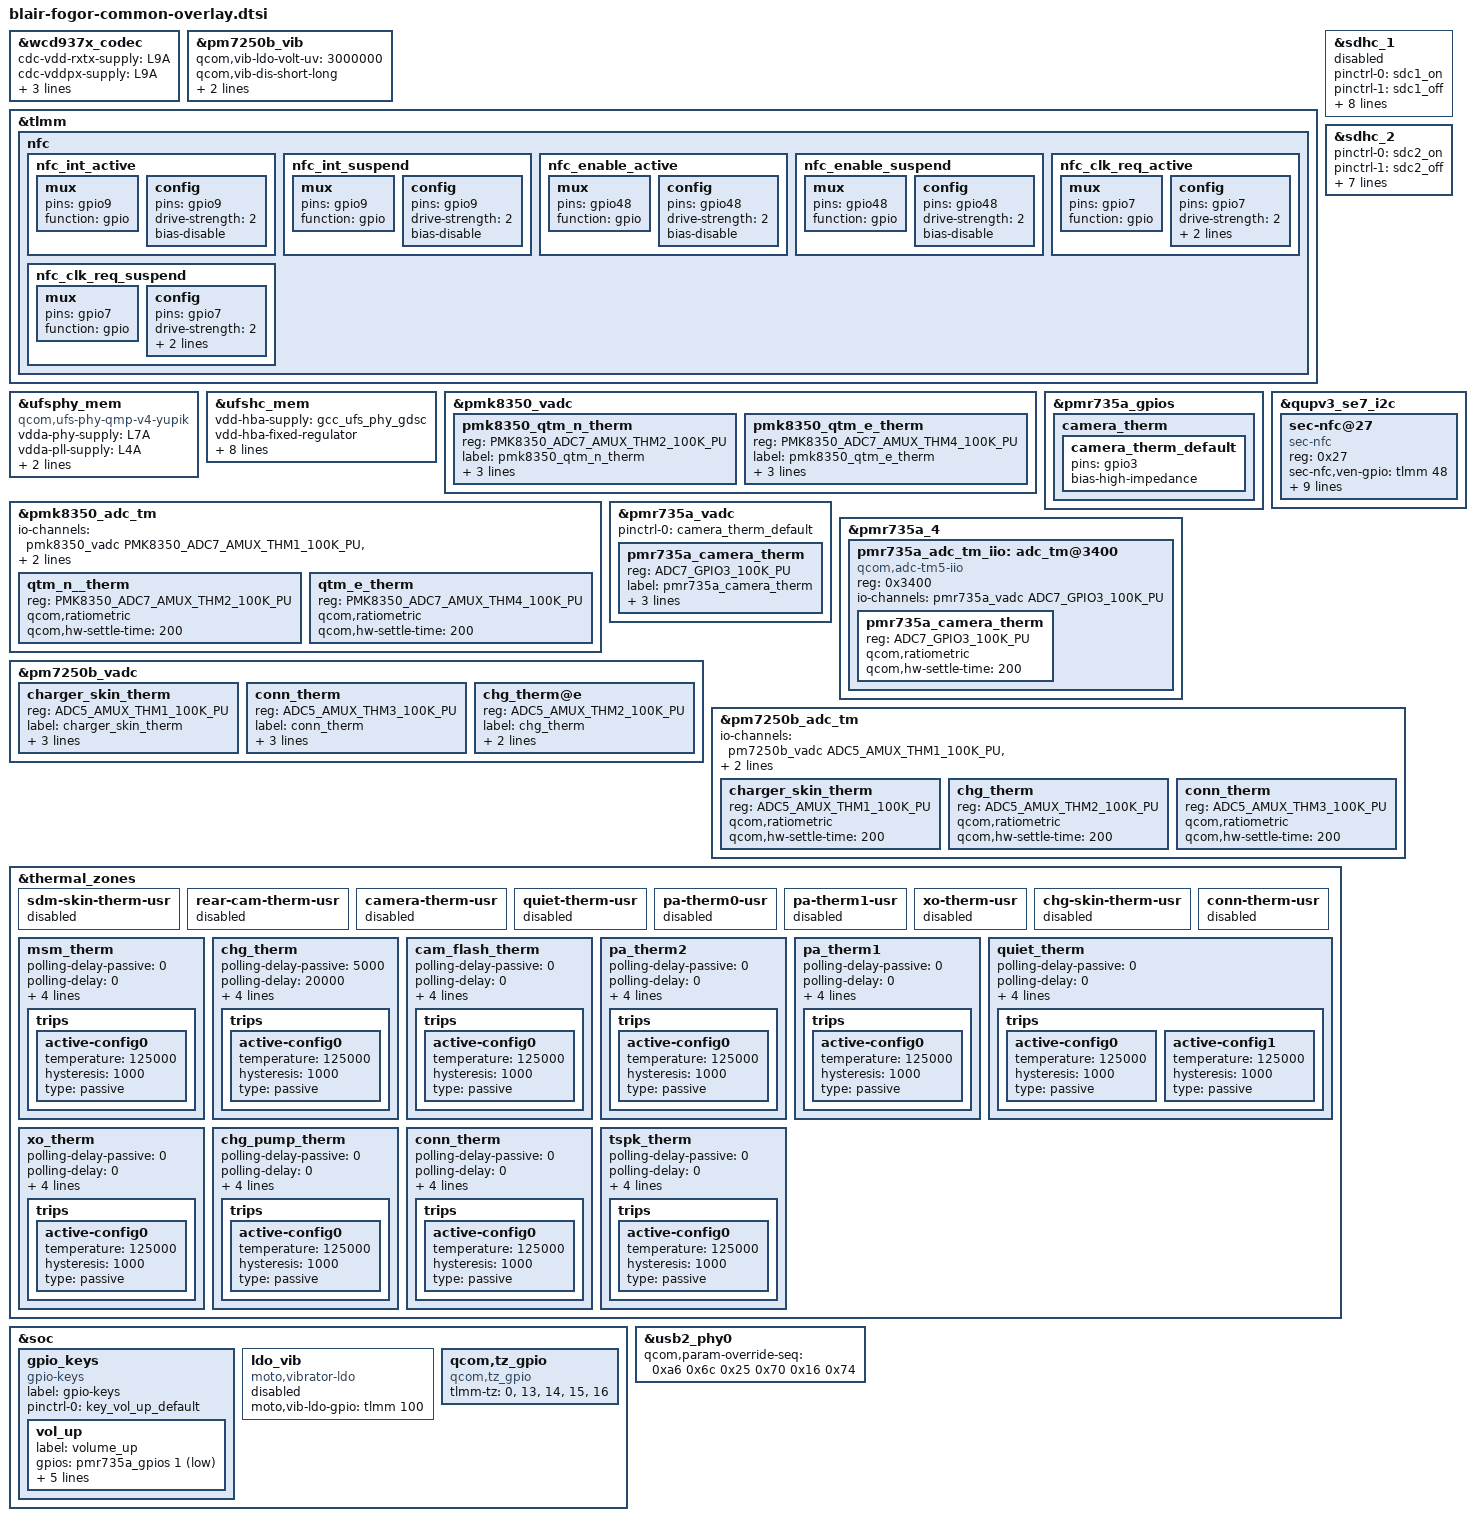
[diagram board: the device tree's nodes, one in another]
/* Copyright (c) 2023, The Linux Foundation. All rights reserved.
 *
 * This program is free software; you can redistribute it and/or modify
 * it under the terms of the GNU General Public License version 2 and
 * only version 2 as published by the Free Software Foundation.
 *
 * This program is distributed in the hope that it will be useful,
 * but WITHOUT ANY WARRANTY; without even the implied warranty of
 * MERCHANTABILITY or FITNESS FOR A PARTICULAR PURPOSE.  See the
 * GNU General Public License for more details.
 */
#include "holi-audio-fogor-overlay.dtsi"
#include <dt-bindings/gpio/gpio.h>
#include <dt-bindings/input/linux-event-codes.h>
#include "holi-pmic-overlay-pm6125.dtsi"
#include "holi-thermal-overlay-pm6125.dtsi"
#include "display/holi-sde-display-mtp-pm6125.dtsi"
#include "display/blair-sde-display-mtp.dtsi"
#include "fogor-fps-overlay.dtsi"
#include "fogor-display.dtsi"
#include "fogor-touchscreen.dtsi"
#include "fogor-sensors.dtsi"
#include "camera/blair-camera-sensor-mot-fogor-overlay.dtsi"
#include "fogor-wl286xx.dtsi"
#include "moto_therm_sys_temp.dtsi"
#include "blair-fogor-fmr-overlay.dtsi"

&wcd937x_codec {
	cdc-vdd-rxtx-supply = <&L9A>;
	cdc-vddpx-supply = <&L9A>;
	qcom,cdc-static-supplies = "cdc-vdd-rxtx",
				   "cdc-vddpx";
	/*
	 * Overriding cdc-vdd-mic-bias-supply to dummy value
	 * to avoid compilation errors as BOB is not definied
	 * for pm6125
	 */
	cdc-vdd-mic-bias-supply = <>;
};

&pm7250b_vib {
	qcom,vib-ldo-volt-uv = <3000000>;
	qcom,vib-dis-short-long;
	qcom,vib-dis-short-long-val = <70>;
	qcom,vib-ldo-volt-uv-long = <2600000>;
};

&tlmm {
	nfc {
		nfc_int_active: nfc_int_active {
			/* active state */
			mux {
				/* GPIO 9: NFC Read Interrupt */
				pins = "gpio9";
				function = "gpio";
			};

			config {
				pins = "gpio9";
				drive-strength = <2>; /* 2 MA */
				bias-disable;
			};
		};

		nfc_int_suspend: nfc_int_suspend {
			/* sleep state */
			mux {
				/* GPIO 9: NFC Read Interrupt */
				pins = "gpio9";
				function = "gpio";
			};

			config {
				pins = "gpio9";
				drive-strength = <2>; /* 2 MA */
				bias-disable;
			};
		};

		nfc_enable_active: nfc_enable_active {
			mux {
				pins = "gpio48";
				function = "gpio";
			};

			config {
				pins = "gpio48";
				drive-strength = <2>; /* 2 MA */
				bias-disable;
			};
		};

		nfc_enable_suspend: nfc_enable_suspend {
			mux {
				pins = "gpio48";
				function = "gpio";
			};

			config {
				pins = "gpio48";
				drive-strength = <2>; /* 2 MA */
				bias-disable;
			};
		};


		nfc_clk_req_active: nfc_clk_req_active {
			/* active state */
			mux {
				/* GPIO 7: NFC CLK Req*/
				pins = "gpio7";
				function = "gpio";
			};

			config {
				pins = "gpio7";
				drive-strength = <2>; /* 2 MA */
				bias-disable;
				input-enable;
			};
		};

		nfc_clk_req_suspend: nfc_clk_req_suspend {
			/* sleep state */
			mux {
				/* GPIO 7: NFC CLK Req */
				pins = "gpio7";
				function = "gpio";
			};

			config {
				pins = "gpio7";
				drive-strength = <2>; /* 2 MA */
				bias-disable;
				input-enable;
			};
		};
	};
};

/* Dummy LDO reference */
&sdhc_1 {
	status = "disabled";

	pinctrl-names = "default", "sleep";
	pinctrl-0 = <&sdc1_on>;
	pinctrl-1 = <&sdc1_off>;

	vdd-supply = <&L24A>;
	qcom,vdd-voltage-level = <2960000 2960000>;
	qcom,vdd-current-level = <0 570000>;

	vdd-io-supply = <&L11A>;
	qcom,vdd-io-always-on;
	qcom,vdd-io-lpm-sup;
	qcom,vdd-io-voltage-level = <1800000 1800000>;
	qcom,vdd-io-current-level = <0 325000>;
};

&sdhc_2 {
	status = "ok";

	pinctrl-names = "default", "sleep";
	pinctrl-0 = <&sdc2_on>;
	pinctrl-1 = <&sdc2_off>;

	vdd-supply = <&L22A>;
	qcom,vdd-voltage-level = <2960000 2960000>;
	qcom,vdd-current-level = <0 800000>;

	vdd-io-supply = <&L5A>;
	qcom,vdd-io-voltage-level = <1800000 2960000>;
	qcom,vdd-io-current-level = <0 22000>;

	cd-gpios = <&tlmm 94 GPIO_ACTIVE_HIGH>;
};

&ufsphy_mem {
		compatible = "qcom,ufs-phy-qmp-v4-yupik";

		vdda-phy-supply = <&L7A>;
		vdda-pll-supply = <&L4A>;
		vdda-phy-max-microamp = <85700>;
		vdda-pll-max-microamp = <18300>;

		status = "ok";
};

&ufshc_mem {
		vdd-hba-supply = <&gcc_ufs_phy_gdsc>;
		vdd-hba-fixed-regulator;

		vcc-supply = <&L24A>;
		vcc-voltage-level = <2950000 2960000>;
		vcc-max-microamp = <800000>;

		vccq2-supply = <&L11A>;
		vccq2-max-microamp = <800000>;
		vccq2-voltage-level = <1800000 1800000>;

		qcom,vddp-ref-clk-supply = <&L4A>;
		qcom,vddp-ref-clk-max-microamp = <100>;

		status = "ok";
};

&pmk8350_vadc {
	pmk8350_qtm_n_therm {
		reg = <PMK8350_ADC7_AMUX_THM2_100K_PU>;
		label = "pmk8350_qtm_n_therm";
		qcom,ratiometric;
		qcom,hw-settle-time = <200>;
		qcom,pre-scaling = <1 1>;
	};
	pmk8350_qtm_e_therm {
		reg = <PMK8350_ADC7_AMUX_THM4_100K_PU>;
		label = "pmk8350_qtm_e_therm";
		qcom,ratiometric;
		qcom,hw-settle-time = <200>;
		qcom,pre-scaling = <1 1>;
	};
};

&pmk8350_adc_tm {
	io-channels = <&pmk8350_vadc PMK8350_ADC7_AMUX_THM1_100K_PU>,
			<&pmk8350_vadc PMK8350_ADC7_AMUX_THM2_100K_PU>,
			<&pmk8350_vadc PMK8350_ADC7_AMUX_THM4_100K_PU>;

	qtm_n__therm {
		reg = <PMK8350_ADC7_AMUX_THM2_100K_PU>;
		qcom,ratiometric;
		qcom,hw-settle-time = <200>;
	};
	qtm_e_therm {
		reg = <PMK8350_ADC7_AMUX_THM4_100K_PU>;
		qcom,ratiometric;
		qcom,hw-settle-time = <200>;
	};
};

&pmr735a_gpios {
	camera_therm {
		camera_therm_default:camera_therm_default {
			pins = "gpio3";
			bias-high-impedance;
		};
	};
};

&pmr735a_vadc {
	status = "ok";

	pinctrl-names = "default";
	pinctrl-0 = <&camera_therm_default>;

	pmr735a_camera_therm {
		reg = <ADC7_GPIO3_100K_PU>;
		label = "pmr735a_camera_therm";
		qcom,ratiometric;
		qcom,hw-settle-time = <200>;
		qcom,pre-scaling = <1 1>;
	};
};

&pmr735a_4{
	pmr735a_adc_tm_iio: adc_tm@3400 {
		compatible = "qcom,adc-tm5-iio";
		reg = <0x3400>;
		#thermal-sensor-cells = <1>;
		#address-cells = <1>;
		#size-cells = <0>;
		io-channels = <&pmr735a_vadc ADC7_GPIO3_100K_PU>;

		pmr735a_camera_therm {
			reg = <ADC7_GPIO3_100K_PU>;
			qcom,ratiometric;
			qcom,hw-settle-time = <200>;
		};
	};
};

&qupv3_se7_i2c {
	status = "ok";
	#address-cells = <1>;
	#size-cells = <0>;
	sec-nfc@27 {
		compatible = "sec-nfc";
		reg = <0x27>;
                sec-nfc,ven-gpio = <&tlmm 48 0x00>;
                sec-nfc,firm-gpio = <&tlmm 135 0x00>;
                sec-nfc,irq-gpio = <&tlmm 9 0x00>;
                sec-nfc,clk_req-gpio = <&tlmm 7 0x00>;
                interrupt-parent = <&tlmm>;
		interrupts = <9 0>;
		interrupt-names = "nfc_irq";
		pinctrl-names = "nfc_active", "nfc_suspend";
		pinctrl-0 = <&nfc_int_active &nfc_enable_active
				&nfc_clk_req_active>;
		pinctrl-1 = <&nfc_int_suspend &nfc_enable_suspend
				&nfc_clk_req_suspend>;
                clock-names = "OSC_NFC";
	};
};

&pm7250b_vadc {
	charger_skin_therm {
		reg = <ADC5_AMUX_THM1_100K_PU>;
		label = "charger_skin_therm";
		qcom,ratiometric;
		qcom,hw-settle-time = <200>;
		qcom,pre-scaling = <1 1>;
	};

	conn_therm {
		reg = <ADC5_AMUX_THM3_100K_PU>;
		label = "conn_therm";
		qcom,ratiometric;
		qcom,hw-settle-time = <200>;
		qcom,pre-scaling = <1 1>;
	};

	chg_therm@e {
		reg = <ADC5_AMUX_THM2_100K_PU>;
		label = "chg_therm";
		qcom,hw-settle-time = <200>;
		qcom,pre-scaling = <1 1>;
	};
};


&pm7250b_adc_tm {
	io-channels = <&pm7250b_vadc ADC5_AMUX_THM1_100K_PU>,
			<&pm7250b_vadc ADC5_AMUX_THM2_100K_PU>,
			<&pm7250b_vadc ADC5_AMUX_THM3_100K_PU>;

	charger_skin_therm {
		reg = <ADC5_AMUX_THM1_100K_PU>;
		qcom,ratiometric;
		qcom,hw-settle-time = <200>;
	};

	chg_therm {
		reg = <ADC5_AMUX_THM2_100K_PU>;
		qcom,ratiometric;
		qcom,hw-settle-time = <200>;
	};

	conn_therm {
		reg = <ADC5_AMUX_THM3_100K_PU>;
		qcom,ratiometric;
		qcom,hw-settle-time = <200>;
	};
};

&thermal_zones {
	sdm-skin-therm-usr {
		status = "disabled";
	};

	rear-cam-therm-usr {
		status = "disabled";
	};

	camera-therm-usr {
		status = "disabled";
	};

	quiet-therm-usr {
		status = "disabled";
	};

	pa-therm0-usr {
		status = "disabled";
	};

	pa-therm1-usr {
		status = "disabled";
	};

	xo-therm-usr {
		status = "disabled";
	};
	chg-skin-therm-usr {
                status = "disabled";
        };

	conn-therm-usr {
                status = "disabled";
        };

	msm_therm {
		polling-delay-passive = <0>;
		polling-delay = <0>;
		thermal-governor = "user_space";
		thermal-sensors = <&pm6125_adc_tm_iio ADC5_GPIO1_100K_PU>;
		wake-capable-sensor;
		trips {
			active-config0 {
				temperature = <125000>;
				hysteresis = <1000>;
				type = "passive";
			};
		};
	};

	chg_therm {
                polling-delay-passive = <5000>;
                polling-delay = <20000>;
                thermal-governor = "user_space";
                thermal-sensors = <&pm7250b_adc_tm ADC5_AMUX_THM1_100K_PU>;
                wake-capable-sensor;
                trips {
                        active-config0 {
                                temperature = <125000>;
                                hysteresis = <1000>;
                                type = "passive";
                        };
                };
        };

	cam_flash_therm {
		polling-delay-passive = <0>;
		polling-delay = <0>;
		thermal-governor = "user_space";
		thermal-sensors = <&pm6125_adc_tm_iio ADC5_GPIO2_100K_PU>;
		wake-capable-sensor;
		trips {
			active-config0 {
				temperature = <125000>;
				hysteresis = <1000>;
				type = "passive";
			};
		};
	};

	pa_therm2 {
		polling-delay-passive = <0>;
		polling-delay = <0>;
		thermal-governor = "user_space";
		thermal-sensors = <&pm6125_adc_tm ADC5_GPIO4_100K_PU>;
		wake-capable-sensor;
		trips {
			active-config0 {
				temperature = <125000>;
				hysteresis = <1000>;
				type = "passive";
			};
		};
	};

	pa_therm1 {
		polling-delay-passive = <0>;
		polling-delay = <0>;
		thermal-governor = "user_space";
		thermal-sensors = <&pm6125_adc_tm ADC5_AMUX_THM1_100K_PU>;
		wake-capable-sensor;
		trips {
			active-config0 {
				temperature = <125000>;
				hysteresis = <1000>;
				type = "passive";
			};
		};
	};

	quiet_therm {
		polling-delay-passive = <0>;
		polling-delay = <0>;
		thermal-governor = "user_space";
		thermal-sensors = <&pm6125_adc_tm ADC5_AMUX_THM2_100K_PU>;
		wake-capable-sensor;
		trips {
			active-config0 {
				temperature = <125000>;
				hysteresis = <1000>;
				type = "passive";
			};

			active-config1 {
				temperature = <125000>;
				hysteresis = <1000>;
				type = "passive";
			};
		};
	};

	xo_therm {
		polling-delay-passive = <0>;
		polling-delay = <0>;
		thermal-governor = "user_space";
		thermal-sensors = <&pmk8350_adc_tm PMK8350_ADC7_AMUX_THM1_100K_PU>;
		wake-capable-sensor;
		trips {
			active-config0 {
				temperature = <125000>;
				hysteresis = <1000>;
				type = "passive";
			};
		};
	};

	chg_pump_therm {
		polling-delay-passive = <0>;
		polling-delay = <0>;
		thermal-governor = "user_space";
		thermal-sensors = <&pm7250b_adc_tm ADC5_AMUX_THM2_100K_PU>;
		wake-capable-sensor;
		trips {
			active-config0 {
				temperature = <125000>;
				hysteresis = <1000>;
				type = "passive";
			};
		};
	};

	conn_therm {
		polling-delay-passive = <0>;
		polling-delay = <0>;
		thermal-governor = "user_space";
		thermal-sensors = <&pm7250b_adc_tm ADC5_AMUX_THM3_100K_PU>;
		wake-capable-sensor;
		trips {
			active-config0 {
				temperature = <125000>;
				hysteresis = <1000>;
				type = "passive";
			};
		};
	};

	tspk_therm {
		polling-delay-passive = <0>;
		polling-delay = <0>;
		thermal-governor = "user_space";
		thermal-sensors = <&pm6125_adc_tm ADC5_GPIO3_100K_PU>;
		wake-capable-sensor;
		trips {
			active-config0 {
				temperature = <125000>;
				hysteresis = <1000>;
				type = "passive";
			};
		};
	};
};

&soc {
	gpio_keys {
		compatible = "gpio-keys";
		label = "gpio-keys";

		pinctrl-names = "default";
		pinctrl-0 = <&key_vol_up_default>;

		vol_up {
			label = "volume_up";
			gpios = <&pmr735a_gpios 1 GPIO_ACTIVE_LOW>;
			linux,input-type = <1>;
			linux,code = <KEY_VOLUMEUP>;
			gpio-key,wakeup;
			debounce-interval = <15>;
			linux,can-disable;
		};
	};

	ldo_vib {
		compatible = "moto,vibrator-ldo";
		moto,vib-ldo-gpio = <&tlmm 100 0x0>;
		status = "disabled";
	};

	qcom,tz_gpio {
		compatible = "qcom,tz_gpio";
		tlmm-tz = <0>,
			<13>,
			<14>,
			<15>,
			<16>;
	};
};

/* Primary USB port related QUSB2 PHY */
&usb2_phy0 {
	qcom,param-override-seq =
	<0xa6 0x6c	/* override_x0 */
	 0x25 0x70	/* override_x1 */
	 0x16 0x74>;	/* override x2 */
};

